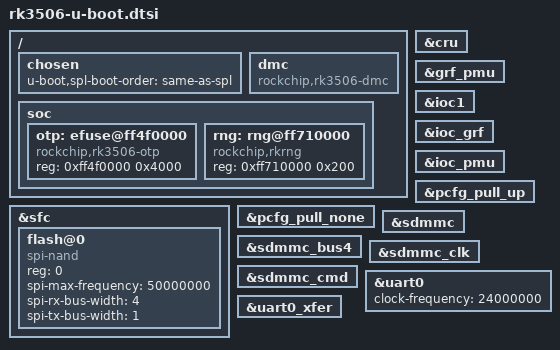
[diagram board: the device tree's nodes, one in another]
// SPDX-License-Identifier: (GPL-2.0+ OR MIT)

#include "rockchip-u-boot.dtsi"

/ {
	chosen {
		u-boot,spl-boot-order = "same-as-spl", &sdmmc;
	};

	dmc {
		compatible = "rockchip,rk3506-dmc";
		bootph-all;
	};

	soc {
		otp: efuse@ff4f0000 {
			compatible = "rockchip,rk3506-otp";
			reg = <0xff4f0000 0x4000>;
		};

		rng: rng@ff710000 {
			compatible = "rockchip,rkrng";
			reg = <0xff710000 0x200>;
		};
	};
};

&cru {
	bootph-all;
};

&grf_pmu {
	bootph-all;
};

&sfc {
	bootph-all;
	status = "okay";

	flash@0 {
		compatible = "spi-nand";
		reg = <0>;
		/* 50 MHz + DLL. RW writes were corrupt at all speeds — root cause was
		 * the SFC TX-FIFO level mask width (5-bit vs RK3506's 6-bit); fixed in
		 * the driver. Back to target 50 MHz. U-Boot's FSPI clk reads 100 MHz
		 * (rk3506 cru set_rate no-op) but it only reads the kernel FIT. */
		spi-max-frequency = <50000000>;
		spi-rx-bus-width = <4>;
		spi-tx-bus-width = <1>;
		bootph-all;
	};
};

&ioc1 {
	bootph-all;
};

&ioc_grf {
	bootph-all;
};

&ioc_pmu {
	bootph-all;
};

&otp {
	bootph-some-ram;
};

&pcfg_pull_none {
	bootph-all;
};

&pcfg_pull_up {
	bootph-all;
};

&sdmmc {
	bootph-pre-ram;
	bootph-some-ram;
};

&sdmmc_bus4 {
	bootph-pre-ram;
	bootph-some-ram;
};

&sdmmc_clk {
	bootph-pre-ram;
	bootph-some-ram;
};

&sdmmc_cmd {
	bootph-pre-ram;
	bootph-some-ram;
};

&uart0 {
	bootph-all;
	clock-frequency = <24000000>;
};

&uart0_xfer {
	bootph-pre-sram;
	bootph-pre-ram;
};
